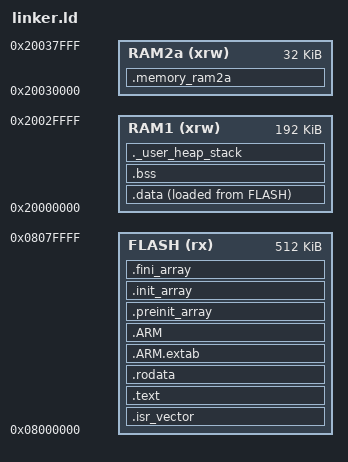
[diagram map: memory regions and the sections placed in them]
/*
 * linker.ld — Linker script for STM32WB55CGU6
 * LumiCast — Open-Source Circadian Light & SPD Analyzer
 *
 * Author: jayis1
 * Copyright (c) 2026 jayis1. All rights reserved.
 * SPDX-License-Identifier: GPL-2.0
 *
 * Memory layout for STM32WB55CGU6 (1 MB Flash, 256 KB SRAM1, 64 KB SRAM2).
 * The Cortex-M0+ core and its shared SRAM2a region are reserved for the
 * BLE stack; the M4 application uses SRAM1 for its main memory.
 */

ENTRY(Reset_Handler)

MEMORY
{
    FLASH (rx)  : ORIGIN = 0x08000000, LENGTH = 512K
    RAM1  (xrw) : ORIGIN = 0x20000000, LENGTH = 192K
    RAM2a (xrw) : ORIGIN = 0x20030000, LENGTH = 32K   /* shared with M0+ */
}

_estack = ORIGIN(RAM1) + LENGTH(RAM1);

SECTIONS
{
    .isr_vector :
    {
        . = ALIGN(4);
        KEEP(*(.isr_vector))
        . = ALIGN(4);
    } > FLASH

    .text :
    {
        . = ALIGN(4);
        *(.text)
        *(.text*)
        *(.glue_7)
        *(.glue_7t)
        *(.eh_frame)

        KEEP(*(.init))
        KEEP(*(.fini))

        . = ALIGN(4);
        _etext = .;
    } > FLASH

    .rodata :
    {
        . = ALIGN(4);
        *(.rodata)
        *(.rodata*)
        . = ALIGN(4);
    } > FLASH

    .ARM.extab :
    {
        *(.ARM.extab* .gnu*)
    } > FLASH

    .ARM :
    {
        __exidx_start = .;
        *(.ARM.exidx*)
        __exidx_end = .;
    } > FLASH

    .preinit_array :
    {
        PROVIDE_HIDDEN(__preinit_array_start = .);
        KEEP(*(.preinit_array*))
        PROVIDE_HIDDEN(__preinit_array_end = .);
    } > FLASH

    .init_array :
    {
        PROVIDE_HIDDEN(__init_array_start = .);
        KEEP(*(SORT(.init_array.*)))
        KEEP(*(.init_array*))
        PROVIDE_HIDDEN(__init_array_end = .);
    } > FLASH

    .fini_array :
    {
        PROVIDE_HIDDEN(__fini_array_start = .);
        KEEP(*(SORT(.fini_array.*)))
        KEEP(*(.fini_array*))
        PROVIDE_HIDDEN(__fini_array_end = .);
    } > FLASH

    _sidata = LOADADDR(.data);

    .data :
    {
        . = ALIGN(4);
        _sdata = .;
        *(.data)
        *(.data*)
        . = ALIGN(4);
        _edata = .;
    } > RAM1 AT > FLASH

    .bss :
    {
        . = ALIGN(4);
        _sbss = .;
        __bss_start__ = _sbss;
        *(.bss)
        *(.bss*)
        *(COMMON)
        . = ALIGN(4);
        _ebss = .;
        __bss_end__ = _ebss;
    } > RAM1

    ._user_heap_stack :
    {
        . = ALIGN(8);
        PROVIDE(end = .);
        PROVIDE(_end = .);
        . = . + 0x400;
        . = ALIGN(8);
    } > RAM1

    .memory_ram2a (NOLOAD) :
    {
        *(.ram2a)
        *(.ram2a*)
    } > RAM2a

    /DISCARD/ :
    {
        libc.a (*)
        libm.a (*)
        libgcc.a (*)
    }

    ASSERT(_estack > _end, "stack overflow")
}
